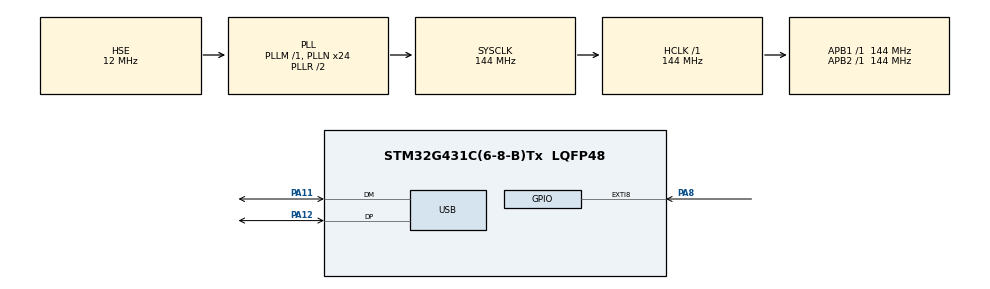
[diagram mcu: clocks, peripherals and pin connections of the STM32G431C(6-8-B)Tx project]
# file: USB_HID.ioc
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Mcu.Family=STM32G4
Mcu.Name=STM32G431C(6-8-B)Tx
Mcu.Package=LQFP48
NVIC.EXTI9_5_IRQn=true\:0\:0\:false\:false\:true\:true\:true\:true
NVIC.PriorityGroup=NVIC_PRIORITYGROUP_4
NVIC.USB_LP_IRQn=true\:0\:0\:false\:false\:true\:false\:true\:true
PA11.Mode=Device
PA11.Signal=USB_DM
PA12.Mode=Device
PA12.Signal=USB_DP
PA8.GPIO_ModeDefaultEXTI=GPIO_MODE_IT_FALLING
PA8.GPIO_PuPd=GPIO_PULLUP
PA8.Signal=GPXTI8
PF0-OSC_IN.Mode=HSE-External-Oscillator
PF0-OSC_IN.Signal=RCC_OSC_IN
PF1-OSC_OUT.Mode=HSE-External-Oscillator
PF1-OSC_OUT.Signal=RCC_OSC_OUT
ProjectManager.HeapSize=0x200
ProjectManager.StackSize=0x400
ProjectManager.TargetToolchain=MDK-ARM V5.32
RCC.ADC12Freq_Value=144000000
RCC.AHBFreq_Value=144000000
RCC.APB1Freq_Value=144000000
RCC.APB1TimFreq_Value=144000000
RCC.APB2Freq_Value=144000000
RCC.APB2TimFreq_Value=144000000
RCC.CortexFreq_Value=144000000
RCC.EXTERNAL_CLOCK_VALUE=12288000
RCC.HCLKFreq_Value=144000000
RCC.HSE_VALUE=12000000
RCC.HSI48_VALUE=48000000
RCC.HSI_VALUE=16000000
RCC.LSE_VALUE=32768
RCC.PLLN=24
RCC.PLLQ=RCC_PLLQ_DIV6
RCC.PLLSourceVirtual=RCC_PLLSOURCE_HSE
RCC.SYSCLKFreq_VALUE=144000000
RCC.SYSCLKSource=RCC_SYSCLKSOURCE_PLLCLK
RCC.USBFreq_Value=48000000
RCC.VCOOutputFreq_Value=288000000
USB.DeviceSpeed=PCD_SPEED_FULL
USB.Sof_enable=DISABLE
USB.low_power_enable=DISABLE
USB.lpm_enable=DISABLE
USB_DEVICE.CLASS_NAME_FS=HID
USB_DEVICE.CONFIGURATION_STRING_HID_FS=HID Config
USB_DEVICE.HID_FS_BINTERVAL=0xA
USB_DEVICE.INTERFACE_STRING_HID_FS=HID Interface
USB_DEVICE.LANGID_STRING=1033
USB_DEVICE.MANUFACTURER_STRING=STMicroelectronics
USB_DEVICE.PID_HID_FS=22315
USB_DEVICE.PRODUCT_STRING_HID_FS=STM32 Human interface
USB_DEVICE.USBD_DEBUG_LEVEL=0
USB_DEVICE.USBD_MAX_NUM_CONFIGURATION=1
USB_DEVICE.USBD_MAX_NUM_INTERFACES=1
USB_DEVICE.USBD_MAX_STR_DESC_SIZ=512
USB_DEVICE.USBD_SELF_POWERED=1
USB_DEVICE.VID=1155
USB_DEVICE.VirtualMode=Hid
USB_DEVICE.VirtualModeFS=Hid_FS
VP_USB_DEVICE_VS_USB_DEVICE_HID_FS.Mode=HID_FS
board=custom

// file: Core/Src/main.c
/* USER CODE BEGIN Header */
/**
  ******************************************************************************
  * @file           : main.c
  * @brief          : Main program body
  ******************************************************************************
  * @attention
  *
  * Copyright (c) 2022 STMicroelectronics.
  * All rights reserved.
  *
  * This software is licensed under terms that can be found in the LICENSE file
  * in the root directory of this software component.
  * If no LICENSE file comes with this software, it is provided AS-IS.
  *
  ******************************************************************************
  */
/* USER CODE END Header */
#include "main.h"
#include "usb_device.h"

/* USER CODE BEGIN Includes */
#include "usbd_hid.h"

/* USER CODE END Includes */

/* USER CODE BEGIN PV */
extern USBD_HandleTypeDef hUsbDeviceFS;
uint8_t hid_buffer[4] = {0, 0, 0, 0};

/* USER CODE END PV */

void SystemClock_Config(void);
static void MX_GPIO_Init(void);

/* USER CODE BEGIN 0 */
void HAL_GPIO_EXTI_Callback(uint16_t GPIO_Pin)
{
		static uint8_t mode = 0;
		static uint32_t tick = 0;

		/* �������� */
		if(HAL_GetTick() -  tick < 300)
				return;

		tick = HAL_GetTick();

		switch(mode) {
			case 0:hid_buffer[1] =  3;hid_buffer[2] =  0;break;
			case 1:hid_buffer[1] = -3;hid_buffer[2] =  0;break;
			case 2:hid_buffer[1] =  0;hid_buffer[2] =  3;break;
			case 3:hid_buffer[1] =  0;hid_buffer[2] = -3;break;
			case 4:hid_buffer[1] =  0;hid_buffer[2] =  0;break;
			default:break;
		}
		mode++;
		if(mode == 5)
			mode = 0;
}
/* USER CODE END 0 */

int main(void)
{

  /* MCU Configuration--------------------------------------------------------*/

  /* Reset of all peripherals, Initializes the Flash interface and the Systick. */
  HAL_Init();

  /* Configure the system clock */
  SystemClock_Config();

  /* Initialize all configured peripherals */
  MX_GPIO_Init();
  MX_USB_Device_Init();

  /* Infinite loop */
  /* USER CODE BEGIN WHILE */
  while (1)
  {
		HAL_Delay(HID_FS_BINTERVAL);
		USBD_HID_SendReport(&hUsbDeviceFS, hid_buffer, 4);
    /* USER CODE END WHILE */

  }
}

void SystemClock_Config(void)
{
  RCC_OscInitTypeDef RCC_OscInitStruct = {0};
  RCC_ClkInitTypeDef RCC_ClkInitStruct = {0};

  /** Configure the main internal regulator output voltage
  */
  HAL_PWREx_ControlVoltageScaling(PWR_REGULATOR_VOLTAGE_SCALE1);

  /** Initializes the RCC Oscillators according to the specified parameters
  * in the RCC_OscInitTypeDef structure.
  */
  RCC_OscInitStruct.OscillatorType = RCC_OSCILLATORTYPE_HSE;
  RCC_OscInitStruct.HSEState = RCC_HSE_ON;
  RCC_OscInitStruct.PLL.PLLState = RCC_PLL_ON;
  RCC_OscInitStruct.PLL.PLLSource = RCC_PLLSOURCE_HSE;
  RCC_OscInitStruct.PLL.PLLM = RCC_PLLM_DIV1;
  RCC_OscInitStruct.PLL.PLLN = 24;
  RCC_OscInitStruct.PLL.PLLP = RCC_PLLP_DIV2;
  RCC_OscInitStruct.PLL.PLLQ = RCC_PLLQ_DIV6;
  RCC_OscInitStruct.PLL.PLLR = RCC_PLLR_DIV2;
  if (HAL_RCC_OscConfig(&RCC_OscInitStruct) != HAL_OK)
  {
    Error_Handler();
  }

  /** Initializes the CPU, AHB and APB buses clocks
  */
  RCC_ClkInitStruct.ClockType = RCC_CLOCKTYPE_HCLK|RCC_CLOCKTYPE_SYSCLK
                              |RCC_CLOCKTYPE_PCLK1|RCC_CLOCKTYPE_PCLK2;
  RCC_ClkInitStruct.SYSCLKSource = RCC_SYSCLKSOURCE_PLLCLK;
  RCC_ClkInitStruct.AHBCLKDivider = RCC_SYSCLK_DIV1;
  RCC_ClkInitStruct.APB1CLKDivider = RCC_HCLK_DIV1;
  RCC_ClkInitStruct.APB2CLKDivider = RCC_HCLK_DIV1;

  if (HAL_RCC_ClockConfig(&RCC_ClkInitStruct, FLASH_LATENCY_4) != HAL_OK)
  {
    Error_Handler();
  }
}

static void MX_GPIO_Init(void)
{
  GPIO_InitTypeDef GPIO_InitStruct = {0};

  /* GPIO Ports Clock Enable */
  __HAL_RCC_GPIOF_CLK_ENABLE();
  __HAL_RCC_GPIOA_CLK_ENABLE();

  /*Configure GPIO pin : PA8 */
  GPIO_InitStruct.Pin = GPIO_PIN_8;
  GPIO_InitStruct.Mode = GPIO_MODE_IT_FALLING;
  GPIO_InitStruct.Pull = GPIO_PULLUP;
  HAL_GPIO_Init(GPIOA, &GPIO_InitStruct);

  /* EXTI interrupt init*/
  HAL_NVIC_SetPriority(EXTI9_5_IRQn, 0, 0);
  HAL_NVIC_EnableIRQ(EXTI9_5_IRQn);

}

void Error_Handler(void)
{
  __disable_irq();
  while (1)
  {
  }
}
